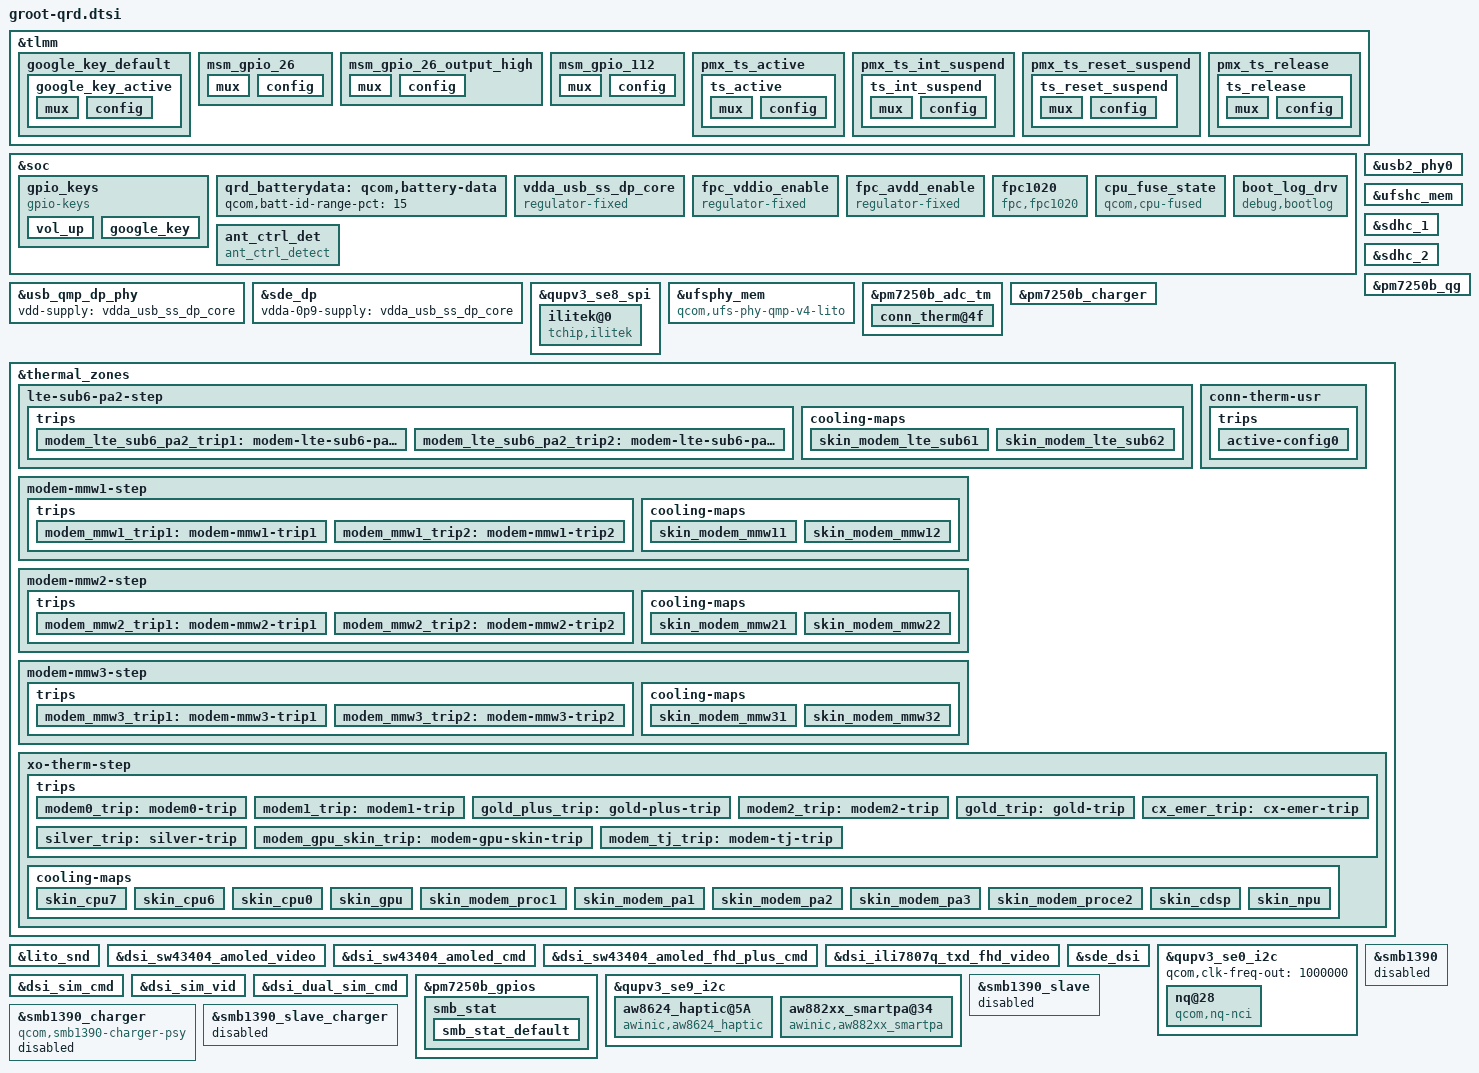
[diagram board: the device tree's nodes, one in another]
#include "lito-pmic-overlay.dtsi"
#include <dt-bindings/gpio/gpio.h>
#include "lito-audio-overlay.dtsi"
#include "lito-thermal-overlay.dtsi"
#include "camera/lito-camera-sensor-qrd.dtsi"
#include "lito-sde-display.dtsi"
#include <dt-bindings/thermal/qmi_thermal.h>

&tlmm {
	google_key_default {
		google_key_active: google_key_active {
			mux {
				pins = "gpio113";
				function = "gpio";
			};

			config {
				pins = "gpio113";
				drive-strength = <8>;
				bias-pull-up;
				input-enable;
			};
		};
	};
};

&soc {
	gpio_keys {
		compatible = "gpio-keys";
		label = "gpio-keys";

		pinctrl-names = "default";
		pinctrl-0 = <&key_vol_up_default>, <&google_key_active>;

		vol_up {
			label = "volume_up";
			gpios = <&pm8150l_gpios 5 GPIO_ACTIVE_LOW>;
			linux,input-type = <1>;
			linux,code = <KEY_VOLUMEUP>;
			gpio-key,wakeup;
			debounce-interval = <15>;
			linux,can-disable;
		};

		google_key {
			label = "google_key";
			gpios = <&tlmm 113 GPIO_ACTIVE_LOW>;
			linux,input-type = <1>;
			linux,code = <KEY_ASSISTANT>;
			gpio-key,wakeup;
			debounce-interval = <15>;
			linux,can-disable;
		};
	};

	qrd_batterydata: qcom,battery-data {
		qcom,batt-id-range-pct = <15>;
		#include "ZQN1876_4540783_4500mAH_May8th2020.dtsi"
	};
	vdda_usb_ss_dp_core: vdda_usb_ss_dp_core {
		compatible = "regulator-fixed";
		regulator-name = "vdd_supply";
		regulator-min-microvolt = <880000>;
		regulator-max-microvolt = <880000>;
		enable-active-high;
		gpio = <&pm8150l_gpios 12 GPIO_ACTIVE_HIGH>;
		pinctrl-names = "default";
		pinctrl-0 = <&usb_eldo13>;
	};

	fpc_vddio_enable: fpc_vddio_enable { //1.8
		compatible = "regulator-fixed";
		regulator-name = "fpc_vddio";
		gpio = <&tlmm 22 0>;
		enable-active-high;
	};

	fpc_avdd_enable: fpc_avdd_enable { //2.8
		compatible = "regulator-fixed";
		regulator-name = "fpc_avdd";
		gpio = <&tlmm 92 0>;
		enable-active-high;
	};

	fpc1020 {
		status = "ok";
		compatible = "fpc,fpc1020";
		interrupt-parent = <&tlmm>;
		interrupts = <112 0x0>;
		fpc,gpio_rst    = <&tlmm 26 0x0>;
		fpc,gpio_irq    = <&tlmm 112 0x0>;

		vdd_io-supply   = <&fpc_vddio_enable>;
		vdd_ana-supply  = <&fpc_avdd_enable>;
//		fpc,enable-on-boot; 
		fpc,enable-wakeup; 

		pinctrl-names = "fpc1020_reset_reset",
			"fpc1020_reset_active",
			"fpc1020_irq_active";

		pinctrl-0 = <&msm_gpio_26>;
		pinctrl-1 = <&msm_gpio_26_output_high>;
		pinctrl-2 = <&msm_gpio_112>;
	};

        cpu_fuse_state {
               compatible = "qcom,cpu-fused";
               qcom,fuse-reg = <0x007805e8>;
               qcom,fuse-anti = <0x007801e4>;
               qcom,fuse-stag2 = <0x007801c0>;
               qcom,fuse-valid-num = <0x00303030>;
               status = "okay";
       };
	boot_log_drv {
		compatible = "debug,bootlog";
		linux,contiguous-region = <&bootlog_mem>;
		second_log_offset = <0x40000>;
		status = "okay";
	};
};

&tlmm {
	/* GPIO_26 : FP_RESET_N */
	msm_gpio_26: msm_gpio_26 {
		mux {
			 pins = "gpio26";
			 function = "gpio";
		};

		config {
			pins = "gpio26";
			drive-strength = <2>;
			bias-disable;
			output-low;
		};
	};

	/* GPIO_26 : FP_RESET_N, state device active*/
	msm_gpio_26_output_high: msm_gpio_26_output_high {
		mux {
			pins = "gpio26";
			function = "gpio";
		};

		config {
			pins = "gpio26";
			drive-strength = <2>;
			bias-disable;
			output-high;
		};
	};

	/* GPIO_112 : FP_INT_N */
	msm_gpio_112: msm_gpio_112 {
		mux {
			pins = "gpio112";
			function = "gpio";
		};

		config {
			pins = "gpio112";
			drive-strength = <2>;
			bias-pull-down;
		};
	};
};

&usb_qmp_dp_phy {
	vdd-supply = <&vdda_usb_ss_dp_core>;
};

&usb2_phy0 {
	qcom,param-override-seq =
		<0xa7 0x6c
		0x0d 0x70
		0x27 0x74>;
};

&sde_dp {
	vdda-0p9-supply = <&vdda_usb_ss_dp_core>;
};

&qupv3_se8_spi{
	status = "ok";
	ilitek@0 {
		compatible = "tchip,ilitek";
		reg = <0x0>;
		//vdd-supply = <&pm8150a_l1>;
		spi-max-frequency = <6000000>;
		interrupt-parent = <&tlmm>;
		interrupts = <9 0x2008>;//9 0x2
		touch,reset-gpio = <&tlmm 8 0x00>;//&tlmm 8 0x01
		touch,irq-gpio = <&tlmm 9 0x2008>;//&tlmm 9 0x02

		pinctrl-names = "pmx_ts_active","pmx_ts_suspend","pmx_ts_release";
		pinctrl-0 = <&ts_active>;
		pinctrl-1 = <&ts_int_suspend &ts_reset_suspend>;
		pinctrl-2 = <&ts_release>;

		panel = <&dsi_ili7807q_txd_fhd_video>;
		touchpanel,rst-gpio = <&tlmm 8 0x00>;
		touchpanel,irq-gpio = <&tlmm 9 0x2008>;
		touchpanel,open_short_not_use_fw;
	};
};

&tlmm {
	pmx_ts_active {
		ts_active: ts_active {
			mux {
				pins = "gpio8", "gpio9";
				function = "gpio";
			};

			config {
				pins = "gpio8", "gpio9";
				drive-strength = <8>;
				bias-pull-up;
			};
		};
	};

	pmx_ts_int_suspend {
		ts_int_suspend: ts_int_suspend {
			mux {
				pins = "gpio9";
				function = "gpio";
			};

			config {
				pins = "gpio9";
				drive-strength = <8>;
				bias-pull-up;
			};
		};
	};

	pmx_ts_reset_suspend {
		ts_reset_suspend: ts_reset_suspend {
			mux {
				pins = "gpio8";
				function = "gpio";
			};

			config {
				pins = "gpio8";
				drive-strength = <8>;
				bias-pull-up;
			};
		};
	};

	pmx_ts_release {
		ts_release: ts_release {
			mux {
				pins = "gpio8", "gpio9";
				function = "gpio";
			};

			config {
				pins = "gpio8", "gpio9";
				drive-strength = <8>;
				bias-pull-up;
			};
		};
	};

};

&ufsphy_mem {
	compatible = "qcom,ufs-phy-qmp-v4-lito";

	vdda-phy-supply = <&pm8150_l5>;
	vdda-pll-supply = <&pm8150_l9>;
	vdda-phy-max-microamp = <90200>;
	vdda-pll-max-microamp = <19000>;

	status = "ok";
};

&ufshc_mem {
	vdd-hba-supply = <&ufs_phy_gdsc>;
	vdd-hba-fixed-regulator;
	vcc-supply = <&pm8150a_l7>;
	vcc-voltage-level = <2950000 2960000>;
	vccq2-supply = <&pm8150_s4>;
	vcc-max-microamp = <800000>;
	vccq2-max-microamp = <800000>;

	qcom,vddp-ref-clk-supply = <&pm8150_l9>;
	qcom,vddp-ref-clk-max-microamp = <100>;
	qcom,vddp-ref-clk-min-uV = <1152000>;
	qcom,vddp-ref-clk-max-uV = <1200000>;
	status = "ok";
};

&sdhc_1 {
	vdd-supply = <&pm8150a_l7>;
	qcom,vdd-voltage-level = <2950000 2950000>;
	qcom,vdd-current-level = <0 570000>;

	vdd-io-supply = <&pm8150_s4>;
	qcom,vdd-io-always-on;
	qcom,vdd-io-lpm-sup;
	qcom,vdd-io-voltage-level = <1800000 1800000>;
	qcom,vdd-io-current-level = <0 325000>;

	pinctrl-names = "active", "sleep";
	pinctrl-0 = <&sdc1_clk_on &sdc1_cmd_on &sdc1_data_on
					&sdc1_rclk_on>;
	pinctrl-1 = <&sdc1_clk_off &sdc1_cmd_off &sdc1_data_off
					&sdc1_rclk_off>;

	status = "ok";
};

&sdhc_2 {
	vdd-supply = <&pm8150a_l9>;
	qcom,vdd-voltage-level = <2950000 2950000>;
	qcom,vdd-current-level = <0 800000>;

	vdd-io-supply = <&pm8150a_l6>;
	qcom,vdd-io-voltage-level = <1800000 2950000>;
	qcom,vdd-io-current-level = <0 22000>;

	pinctrl-names = "active", "sleep";
	pinctrl-0 = <&sdc2_clk_on  &sdc2_cmd_on &sdc2_data_on &sdc2_cd_on>;
	pinctrl-1 = <&sdc2_clk_off &sdc2_cmd_off &sdc2_data_off &sdc2_cd_off>;

	cd-gpios = <&tlmm 69 GPIO_ACTIVE_HIGH>;

	status = "ok";
};

&pm7250b_adc_tm {
	io-channels = <&pm7250b_vadc ADC_AMUX_THM1_PU2>,
			<&pm7250b_vadc ADC_AMUX_THM3_PU2>,
			<&pm7250b_vadc ADC_GPIO2_PU2>,
			<&pm7250b_vadc ADC_GPIO4_PU2>;

	conn_therm@4f {
		reg = <ADC_AMUX_THM3_PU2>;
		qcom,ratiometric;
		qcom,hw-settle-time = <200>;
	};
};

&pm7250b_charger {
	status = "ok";
	io-channels = <&pm7250b_vadc ADC_USB_IN_V_16>,
		      <&pm7250b_vadc ADC_USB_IN_I>,
		      <&pm7250b_vadc ADC_CHG_TEMP>,
		      <&pm7250b_vadc ADC_DIE_TEMP>,
		      <&pm7250b_vadc ADC_AMUX_THM3_PU2>,
		      <&pm7250b_vadc ADC_SBUx>,
		      <&pm7250b_vadc ADC_VPH_PWR>,
		      <&pm7250b_vadc ADC_AMUX_THM1_PU2>;
	io-channel-names = "usb_in_voltage",
			   "usb_in_current",
			   "chg_temp",
			   "die_temp",
			   "conn_temp",
			   "sbux_res",
			   "vph_voltage",
			   "skin_temp";
	qcom,battery-data = <&qrd_batterydata>;
	qcom,sec-charger-config = <0>;	//1 -> smb1390
	qcom,auto-recharge-soc = <98>;
	qcom,step-charging-enable;
	qcom,sw-jeita-enable;
	qcom,charger-temp-max = <800>;
	qcom,smb-temp-max = <800>;
	qcom,suspend-input-on-debug-batt;
	qcom,fcc-stepping-enable;
	qcom,fcc-step-delay-ms = <100>;
	qcom,fcc-step-size-ua = <100000>;
	qcom,smb-internal-pull-kohm = <0>;
	qcom,en-skin-therm-mitigation;
	qcom,thermal-mitigation = <4400000 4000000 3500000 3000000 2500000
				2000000 1500000 1200000 900000 700000 500000>;
};

&pm7250b_qg {
	status = "ok";
	io-channels = <&pm7250b_vadc ADC_BAT_THERM_PU1>,
		      <&pm7250b_vadc ADC_BAT_ID_PU2>;
	io-channel-names = "batt-therm",
			   "batt-id";
	qcom,qg-iterm-ma = <300>;
	qcom,hold-soc-while-full;
	qcom,linearize-soc;
	qcom,cl-feedback-on;
	qcom,vbatt-cutoff-mv = <3400>;
	qcom,vbatt-low-mv = <3500>;
	qcom,vbatt-low-cold-mv = <3700>;
	qcom,vbatt-empty-mv = <3250>;
	qcom,vbatt-empty-cold-mv = <3250>;
	qcom,tcss-enable;
	qcom,tcss-entry-soc = <95>;
	qcom,fvss-enable;
	qcom,fvss-vbatt-mv = <3500>;
	qcom,bass-enable;
};

&thermal_zones {
	lte-sub6-pa2-step {
		polling-delay-passive = <2000>;
		polling-delay = <0>;
		thermal-governor = "step_wise";
		thermal-sensors = <&pm8150l_adc_tm ADC_AMUX_THM1_PU2>;
		wake-capable-sensor;
		trips {
			modem_lte_sub6_pa2_trip1: modem-lte-sub6-pa2-trip1 {
				temperature = <90000>;
				hysteresis = <5000>;
				type = "passive";
			};
			modem_lte_sub6_pa2_trip2: modem-lte-sub6-pa2-trip2 {
				temperature = <100000>;
				hysteresis = <5000>;
				type = "passive";
			};
		};
		cooling-maps {
			skin_modem_lte_sub61 {
				trip = <&modem_lte_sub6_pa2_trip1>;
				cooling-device =
					<&modem_pa_fr1 1 1>;
			};
			skin_modem_lte_sub62 {
				trip = <&modem_lte_sub6_pa2_trip2>;
				cooling-device =
					<&modem_pa_fr1 2 2>;
			};
		};
	};

	modem-mmw1-step {
		polling-delay-passive = <2000>;
		polling-delay = <0>;
		thermal-governor = "step_wise";
		thermal-sensors = <&pm8150l_adc_tm ADC_AMUX_THM3_PU2>;
		wake-capable-sensor;
		trips {
			modem_mmw1_trip1: modem-mmw1-trip1 {
				temperature = <90000>;
				hysteresis = <5000>;
				type = "passive";
			};
			modem_mmw1_trip2: modem-mmw1-trip2 {
				temperature = <100000>;
				hysteresis = <5000>;
				type = "passive";
			};
		};
		cooling-maps {
			skin_modem_mmw11 {
				trip = <&modem_mmw1_trip1>;
				cooling-device =
					<&modem_mmw1 1 1>;
			};
			skin_modem_mmw12 {
				trip = <&modem_mmw1_trip2>;
				cooling-device =
					<&modem_mmw1 2 2>;
			};
		};
	};

	modem-mmw2-step {
		polling-delay-passive = <2000>;
		polling-delay = <0>;
		thermal-governor = "step_wise";
		thermal-sensors = <&pm7250b_adc_tm ADC_GPIO2_PU2>;
		wake-capable-sensor;
		trips {
			modem_mmw2_trip1: modem-mmw2-trip1 {
				temperature = <90000>;
				hysteresis = <5000>;
				type = "passive";
			};
			modem_mmw2_trip2: modem-mmw2-trip2 {
				temperature = <100000>;
				hysteresis = <5000>;
				type = "passive";
			};
		};
		cooling-maps {
			skin_modem_mmw21 {
				trip = <&modem_mmw2_trip1>;
				cooling-device =
					<&modem_mmw2 1 1>;
			};
			skin_modem_mmw22 {
				trip = <&modem_mmw2_trip2>;
				cooling-device =
					<&modem_mmw2 2 2>;
			};
		};
	};

	modem-mmw3-step {
		polling-delay-passive = <2000>;
		polling-delay = <0>;
		thermal-governor = "step_wise";
		thermal-sensors = <&pm8150_adc_tm ADC_AMUX_THM2_PU2>;
		wake-capable-sensor;
		trips {
			modem_mmw3_trip1: modem-mmw3-trip1 {
				temperature = <90000>;
				hysteresis = <5000>;
				type = "passive";
			};
			modem_mmw3_trip2: modem-mmw3-trip2 {
				temperature = <100000>;
				hysteresis = <5000>;
				type = "passive";
			};
		};
		cooling-maps {
			skin_modem_mmw31 {
				trip = <&modem_mmw3_trip1>;
				cooling-device =
					<&modem_mmw3 1 1>;
			};
			skin_modem_mmw32 {
				trip = <&modem_mmw3_trip2>;
				cooling-device =
					<&modem_mmw3 2 2>;
			};
		};
	};

	conn-therm-usr {
		polling-delay-passive = <0>;
		polling-delay = <0>;
		thermal-governor = "user_space";
		thermal-sensors = <&pm7250b_adc_tm ADC_AMUX_THM3_PU2>;
		wake-capable-sensor;
		trips {
			active-config0 {
				temperature = <125000>;
				hysteresis = <1000>;
				type = "passive";
			};
		};
	};


	xo-therm-step {
		polling-delay-passive = <2000>;
		polling-delay = <0>;
		thermal-governor = "step_wise";
		thermal-sensors = <&pm8150_adc_tm ADC_XO_THERM_PU2>;
		wake-capable-sensor;
		trips {
			modem0_trip: modem0-trip {
				temperature = <100000>;
				hysteresis = <130000>;
				type = "passive";
			};

			modem1_trip: modem1-trip {
				temperature = <100000>;
				hysteresis = <130000>;
				type = "passive";
			};

			gold_plus_trip: gold-plus-trip {
				temperature = <50000>;
				hysteresis = <0>;
				type = "passive";
			};

			modem2_trip: modem2-trip {
				temperature = <100000>;
				hysteresis = <130000>;
				type = "passive";
			};

			gold_trip: gold-trip {
				temperature = <52000>;
				hysteresis = <0>;
				type = "passive";
			};

			cx_emer_trip: cx-emer-trip {
				temperature = <54000>;
				hysteresis = <6000>;
				type = "passive";
			};

			silver_trip: silver-trip {
				temperature = <54000>;
				hysteresis = <0>;
				type = "passive";
			};

			modem_gpu_skin_trip: modem-gpu-skin-trip {
				temperature = <56000>;
				hysteresis = <4000>;
				type = "passive";
			};
			modem_tj_trip:modem-tj-trip {
                                temperature = <100000>;
                                hysteresis = <130000>;
                                type = "passive";
			};

		};

		cooling-maps {
			skin_cpu7 {
				trip = <&gold_plus_trip>;
					/* throttle from fmax to 1516800KHz */
				cooling-device =
					<&CPU7 THERMAL_NO_LIMIT
						(THERMAL_MAX_LIMIT-3)>;
			};

			skin_cpu6 {
				trip = <&gold_trip>;
					/* throttle from fmax to 1478400KHz */
				cooling-device =
					<&CPU6 THERMAL_NO_LIMIT
						(THERMAL_MAX_LIMIT-3)>;
			};

			skin_cpu0 {
				trip = <&silver_trip>;
					/* throttle from fmax to 1459200KHz */
				cooling-device = <&CPU0 THERMAL_NO_LIMIT
						(THERMAL_MAX_LIMIT-5)>;
			};

			skin_gpu {
				trip = <&modem_gpu_skin_trip>;
				cooling-device = <&msm_gpu (THERMAL_MAX_LIMIT-1)
						(THERMAL_MAX_LIMIT-1)>;
			};

			skin_modem_proc1 {
				trip = <&modem0_trip>;
				cooling-device = <&modem_tj 1 1>;
			};

			skin_modem_pa1 {
				trip = <&modem1_trip>;
				cooling-device = <&modem_pa 1 1>;
			};

			skin_modem_pa2 {
				trip = <&modem2_trip>;
				cooling-device = <&modem_pa 2 2>;
			};

			skin_modem_pa3 {
				trip = <&modem_tj_trip>;
				cooling-device = <&modem_pa 3 3>;
			};

			skin_modem_proce2 {
				trip = <&modem_tj_trip>;
				cooling-device = <&modem_tj 3 3>;
			};

			skin_cdsp {
				trip = <&cx_emer_trip>;
				cooling-device = <&msm_cdsp_rm 3 3>;
			};

			skin_npu {
				trip = <&cx_emer_trip>;
				cooling-device = <&msm_npu THERMAL_MAX_LIMIT
						THERMAL_MAX_LIMIT>;
			};
		};
	};
};



&lito_snd {
	qcom,model = "lito-qrd-snd-card";
	qcom,audio-routing =
		"AMIC1", "MIC BIAS1",
		"MIC BIAS1", "Analog Mic1",
		"AMIC2", "MIC BIAS2",
		"MIC BIAS2", "Analog Mic2",
		"AMIC3", "MIC BIAS3",
		"MIC BIAS3", "Analog Mic3",
		"TX DMIC0", "MIC BIAS3",
		"MIC BIAS3", "Digital Mic0",
		"TX DMIC1", "MIC BIAS3",
		"MIC BIAS3", "Digital Mic1",
		"TX DMIC2", "MIC BIAS1",
		"MIC BIAS1", "Digital Mic2",
		"TX DMIC3", "MIC BIAS1",
		"MIC BIAS1", "Digital Mic3",
		"TX DMIC4", "MIC BIAS4",
		"MIC BIAS4", "Digital Mic4",
		"TX DMIC5", "MIC BIAS4",
		"MIC BIAS4", "Digital Mic5",
		"IN1_HPHL", "HPHL_OUT",
		"IN2_HPHR", "HPHR_OUT",
		"IN3_AUX", "AUX_OUT",
		"TX SWR_ADC0", "ADC1_OUTPUT",
		"TX SWR_ADC1", "ADC2_OUTPUT",
		"TX SWR_ADC2", "ADC3_OUTPUT",
		"TX SWR_ADC3", "ADC4_OUTPUT",
		"TX SWR_DMIC0", "DMIC1_OUTPUT",
		"TX SWR_DMIC1", "DMIC2_OUTPUT",
		"TX SWR_DMIC2", "DMIC3_OUTPUT",
		"TX SWR_DMIC3", "DMIC4_OUTPUT",
		"TX SWR_DMIC4", "DMIC5_OUTPUT",
		"TX SWR_DMIC5", "DMIC6_OUTPUT",
		"TX SWR_DMIC6", "DMIC7_OUTPUT",
		"TX SWR_DMIC7", "DMIC8_OUTPUT",
		"WSA SRC0_INP", "SRC0",
		"WSA_TX DEC0_INP", "TX DEC0 MUX",
		"WSA_TX DEC1_INP", "TX DEC1 MUX",
		"RX_TX DEC0_INP", "TX DEC0 MUX",
		"RX_TX DEC1_INP", "TX DEC1 MUX",
		"RX_TX DEC2_INP", "TX DEC2 MUX",
		"RX_TX DEC3_INP", "TX DEC3 MUX",
		"SpkrRight IN", "WSA_SPK2 OUT",
		"VA_AIF1 CAP", "VA_SWR_CLK",
		"VA_AIF2 CAP", "VA_SWR_CLK",
		"VA_AIF3 CAP", "VA_SWR_CLK",
		"VA MIC BIAS3", "Digital Mic0",
		"VA MIC BIAS3", "Digital Mic1",
		"VA MIC BIAS1", "Digital Mic2",
		"VA MIC BIAS1", "Digital Mic3",
		"VA MIC BIAS4", "Digital Mic4",
		"VA MIC BIAS4", "Digital Mic5",
		"VA DMIC0", "VA MIC BIAS3",
		"VA DMIC1", "VA MIC BIAS3",
		"VA DMIC2", "VA MIC BIAS1",
		"VA DMIC3", "VA MIC BIAS1",
		"VA DMIC4", "VA MIC BIAS4",
		"VA DMIC5", "VA MIC BIAS4",
		"VA SWR_ADC0", "VA_SWR_CLK",
		"VA SWR_ADC1", "VA_SWR_CLK",
		"VA SWR_ADC2", "VA_SWR_CLK",
		"VA SWR_ADC3", "VA_SWR_CLK",
		"VA SWR_MIC0", "VA_SWR_CLK",
		"VA SWR_MIC1", "VA_SWR_CLK",
		"VA SWR_MIC2", "VA_SWR_CLK",
		"VA SWR_MIC3", "VA_SWR_CLK",
		"VA SWR_MIC4", "VA_SWR_CLK",
		"VA SWR_MIC5", "VA_SWR_CLK",
		"VA SWR_MIC6", "VA_SWR_CLK",
		"VA SWR_MIC7", "VA_SWR_CLK",
		"VA SWR_ADC1", "ADC2_OUTPUT",
		"VA SWR_MIC0", "DMIC1_OUTPUT",
		"VA SWR_MIC1", "DMIC2_OUTPUT",
		"VA SWR_MIC0", "DMIC1_OUTPUT",
		"VA SWR_MIC1", "DMIC2_OUTPUT",
		"VA SWR_MIC2", "DMIC3_OUTPUT",
		"VA SWR_MIC3", "DMIC4_OUTPUT",
		"VA SWR_MIC4", "DMIC5_OUTPUT",
		"VA SWR_MIC5", "DMIC6_OUTPUT",
		"VA SWR_MIC6", "DMIC7_OUTPUT",
		"VA SWR_MIC7", "DMIC8_OUTPUT";
	qcom,wsa-max-devs = <0>;
	qcom,wsa-aux-dev-prefix = "SpkrRight", "SpkrRight";
	qcom,msm-mbhc-usbc-audio-supported = <0>;
	qcom,msm-mbhc-hphl-swh = <1>;
	qcom,msm-mbhc-gnd-swh = <1>;
	qcom,mi2s-audio-intf = <1>;
	qcom,ext-disp-audio-rx = <0>;
	qcom,sec-mi2s-gpios = <&cdc_sec_mi2s_gpios>;
	pinctrl-names =	"ext_spk_pa_act",
			"ext_spk_pa_sus";
	pinctrl-0 = <&ext_spk_pa_act>;
	pinctrl-1 = <&ext_spk_pa_sus>;

	qcom,ext-spk-pa-gpio = <&tlmm 24 0>;
};

&dsi_sw43404_amoled_video {
	qcom,panel-supply-entries = <&dsi_panel_pwr_supply>;
	qcom,mdss-dsi-bl-pmic-control-type = "bl_ctrl_dcs";
	qcom,mdss-dsi-bl-min-level = <1>;
	qcom,mdss-dsi-bl-max-level = <1023>;
	qcom,mdss-brightness-max-level = <255>;
	qcom,platform-te-gpio = <&tlmm 10 0>;
	qcom,platform-reset-gpio = <&pm8150l_gpios 3 0>;
};

&dsi_sw43404_amoled_cmd {
	qcom,panel-supply-entries = <&dsi_panel_pwr_supply>;
	qcom,mdss-dsi-bl-pmic-control-type = "bl_ctrl_dcs";
	qcom,mdss-dsi-bl-min-level = <1>;
	qcom,mdss-dsi-bl-max-level = <1023>;
	qcom,mdss-brightness-max-level = <255>;
	qcom,platform-te-gpio = <&tlmm 10 0>;
	qcom,platform-reset-gpio = <&pm8150l_gpios 3 0>;
};

&dsi_sw43404_amoled_fhd_plus_cmd {
	qcom,panel-supply-entries = <&dsi_panel_pwr_supply>;
	qcom,mdss-dsi-bl-pmic-control-type = "bl_ctrl_dcs";
	qcom,mdss-dsi-bl-min-level = <1>;
	qcom,mdss-dsi-bl-max-level = <1023>;
	qcom,mdss-brightness-max-level = <255>;
	qcom,platform-te-gpio = <&tlmm 10 0>;
	qcom,platform-reset-gpio = <&pm8150l_gpios 3 0>;
};

&dsi_ili7807q_txd_fhd_video {
    qcom,panel-supply-entries = <&dsi_panel_pwr_supply>;
    qcom,mdss-dsi-bl-pmic-control-type = "bl_ctrl_wled";
    qcom,mdss-dsi-bl-min-level = <1>;
    qcom,mdss-dsi-bl-max-level = <4095>;
    qcom,mdss-brightness-max-level = <255>;
    //qcom,platform-tp-rst-gpio = <&tlmm 8 0>;
    qcom,platform-pw8418-rst-gpio = <&tlmm 33 0>;
    qcom,platform-reset-gpio = <&pm8150l_gpios 3 0>;
    qcom,panel-supply-entries = <&dsi_panel_pwr_supply_labibb>;
};

&sde_dsi {
	qcom,dsi-default-panel = <&dsi_ili7807q_txd_fhd_video>;
};

&qupv3_se0_i2c {
	status = "ok";
	qcom,clk-freq-out = <1000000>;
	#address-cells = <1>;
	#size-cells = <0>;
	nq@28 {
		compatible = "qcom,nq-nci";
		reg = <0x28>;
		qcom,nq-irq = <&tlmm 34 0x00>;
		qcom,nq-ven = <&tlmm 12 0x00>;
		qcom,nq-firm = <&tlmm 35 0x00>;
		qcom,nq-clkreq = <&tlmm 31 0x00>;
		interrupt-parent = <&tlmm>;
		interrupts = <34 0>;
		interrupt-names = "nfc_irq";
		pinctrl-names = "nfc_active", "nfc_suspend";
		pinctrl-0 = <&nfc_int_active &nfc_enable_active
				&nfc_clk_req_active>;
		pinctrl-1 = <&nfc_int_suspend &nfc_enable_suspend
				&nfc_clk_req_suspend>;
	};
};

&dsi_sim_cmd {
	qcom,panel-supply-entries = <&dsi_panel_pwr_supply>;
	qcom,mdss-dsi-bl-pmic-control-type = "bl_ctrl_dcs";
	qcom,platform-reset-gpio = <&pm8150l_gpios 3 0>;
};

&dsi_sim_vid {
	qcom,panel-supply-entries = <&dsi_panel_pwr_supply>;
	qcom,mdss-dsi-bl-pmic-control-type = "bl_ctrl_dcs";
	qcom,platform-reset-gpio = <&pm8150l_gpios 3 0>;
};

&dsi_dual_sim_cmd {
	qcom,panel-supply-entries = <&dsi_panel_pwr_supply>;
	qcom,mdss-dsi-bl-pmic-control-type = "bl_ctrl_dcs";
	qcom,platform-reset-gpio = <&pm8150l_gpios 3 0>;
};

&dsi_dual_sim_cmd {
	qcom,panel-supply-entries = <&dsi_panel_pwr_supply>;
	qcom,mdss-dsi-bl-pmic-control-type = "bl_ctrl_dcs";
	qcom,platform-reset-gpio = <&pm8150l_gpios 3 0>;
};

&pm7250b_gpios {
	smb_stat {
		smb_stat_default: smb_stat_default {
			pins = "gpio6";
			function = "normal";
			input-enable;
			bias-pull-up;
			qcom,pull-up-strength = <PMIC_GPIO_PULL_UP_30>;
			power-source = <0>;
		};
	};
};

&qupv3_se9_i2c {
	status = "ok";
	#include "smb1390.dtsi"


	/* AWINIC AW8624 Haptic */
	aw8624_haptic@5A {
		compatible = "awinic,aw8624_haptic", "ti,drv2624";
		reg = <0x5A>;
		reset-gpio = <&tlmm 4 0>;
		vib_mode = < 0 >;  /*mode:  RAM mode->0; CONT mode -> 1*/
		vib_f0_pre = < 2350 >;
		vib_f0_cali_percen = < 7 >;
		vib_cont_drv_lev = < 125 >;
		vib_cont_drv_lvl_ov = < 155 >;
		vib_cont_td = < 0xF06C >;
		vib_cont_zc_thr = < 0x08F8 >;
		vib_cont_num_brk = < 3 >;
		vib_f0_coeff = < 260 >; /*Don't modify it*/
		vib_duration_time = < 20 30 60 0 0 >;
		vib_brake_cont_config = < 1 1 90 42 20 5 2 2 0 0 0  0  0  0 0 0 0 0 0   0  0  0 0 0 >;
		vib_f0_trace_parameter = < 9 5 1 15 >;
		vib_bemf_config = < 0x10 0x08 0x23 0xf8 >;
		vib_sw_brake = < 0x2c >;
		vib_wavseq = < 1 2 3 4 5 6 7 8 9 10 0 0 0 0 0 0 >; /*wavseq1-seq8 0x07-0x0E*/
		vib_wavloop = < 1 1 1 1 1 1 1 1 1 1>;/*loop1-mainloog 0x0f-0x13*/
		vib_td_brake = < 42720 42720 42720 >; /*level0  level1  level2*/
		vib_tset = < 0x11 >;
		vib_func_parameter1 = < 1 >;

		/* TI DRV2624 Haptic */
		ti,smart-loop = <0>; /* 0-closeloop, 1-openloop */
		ti,actuator = <1>; /* 0-ERM, 1-LRA */
		ti,rated-voltage = <1800>;  /* 1800 mv */
		ti,odclamp-voltage = <1850>;	/*3000 mv */
		ti,lra-frequency = <235>; /* DON'T Care if ERM */
		/* TI DRV2624 Haptic End */
		status = "ok";
	};
	/* AWINIC AW8624 Haptic End */

	/* AWINIC AW882XX mono Smart PA */
	aw882xx_smartpa@34 {
	compatible = "awinic,aw882xx_smartpa";
	reg = <0x34>;
	reset-gpio = <&tlmm 58 0>;
	irq-gpio = <&tlmm 56 0x2008>;
	monitor-flag = <1>;
	monitor-timer-val = <3000>;
	status = "okay";
	aw-cali-mode = "aw_misc";
	};
	/* AWINIC AW882XX mono Smart PA End */
};

&smb1390 {
	/delete-property/ interrupts;
	interrupts = <0x2 0xc5 0x0 IRQ_TYPE_LEVEL_LOW>;
	pinctrl-names = "default";
	pinctrl-0 = <&smb_stat_default>;
	status = "disable";
};

&smb1390_charger {
	compatible = "qcom,smb1390-charger-psy";
	io-channels = <&pm7250b_vadc ADC_AMUX_THM2>;
	io-channel-names = "cp_die_temp";
	qcom,parallel-input-mode = <1>; /* USBIN */
	qcom,parallel-output-mode = <2>; /* VBAT */
	qcom,min-ilim-ua = <750000>;
	status = "disable";
};

&smb1390_slave {
	status = "disable";
};

&smb1390_slave_charger {
	status = "disable";
};

&soc {
	ant_ctrl_det {
		compatible = "ant_ctrl_detect";

		pinctrl-names = "default";
		pinctrl-0 = <&ant_ctrl_det_default>;
		gpios = <&tlmm 64 0>,
			<&tlmm 65 0>,
			<&tlmm 90 0>,
			<&tlmm 100 0>,
			<&tlmm 121 0>,
			<&tlmm 126 0>,
			<&tlmm 127 0>,
			<&tlmm 128 0>;
	};
};
